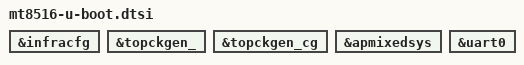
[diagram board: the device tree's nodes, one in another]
// SPDX-License-Identifier: (GPL-2.0 OR MIT)
/*
 * Copyright (C) 2019 BayLibre, SAS
 * Author: Fabien Parent <fparent@baylibre.com>
 */

&infracfg {
	u-boot,dm-all;
};

&topckgen_ {
	u-boot,dm-all;
};

&topckgen_cg {
	u-boot,dm-all;
};

&apmixedsys {
	u-boot,dm-all;
};

&uart0 {
	u-boot,dm-all;
};
